# R7FA4L1BD register map
Vendor: Renesas Electronics Corporation; Series: RA4; File version: 1.20.03
CPU: CM33 r0p4, little endian, MPU, FPU, VTOR, 4 interrupt priority bits, 96 interrupts
Registers are 32-bit, read-write, reset 0x0 unless marked. A register's access mark holds for its fields unless they carry their own. Offsets are from the block's base; [hi:lo] are bit positions; 'fields as' and 'values as' point back to an identical list.

## MSTP — Module Stop Control
Base 0x40084000
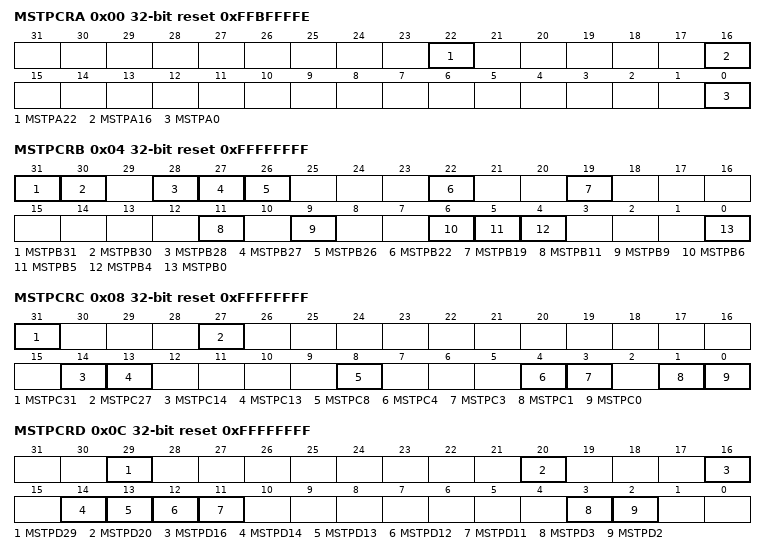
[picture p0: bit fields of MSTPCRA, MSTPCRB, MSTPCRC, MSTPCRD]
0x00 MSTPCRA reset 0xFFBFFFFE — Module Stop Control Register A
  [all] fields
    0=Cancel the module-stop state; 1=Enter the module-stop state
  [22] MSTPA22 — DMA Controller/Data Transfer Controller Module Stop
  [16] MSTPA16 — Sub Oscillation Stop Detection Module Stop
  [0] MSTPA0 — SRAM0 Module Stop
0x04 MSTPCRB reset 0xFFFFFFFF — Module Stop Control Register B
  [all] fields
    values as the fields of MSTPCRA
  [31] MSTPB31 — Serial Communication Interface 0 Module Stop
  [30] MSTPB30 — Serial Communication Interface 1 Module Stop
  [28] MSTPB28 — Serial Communication Interface 3 Module Stop
  [27] MSTPB27 — Serial Communication Interface 4 Module Stop
  [26] MSTPB26 — Serial Communication Interface 5 Module Stop
  [22] MSTPB22 — Serial Communication Interface 9 Module Stop
  [19] MSTPB19 — Serial Peripheral Interface 0 Module Stop
  [11] MSTPB11 — Universal Serial Bus 2.0 FS Interface Module Stop
  [9] MSTPB9 — I2C Bus Interface 0 Module Stop
  [6] MSTPB6 — Quad Serial Peripheral Interface Module Stop
  [5] MSTPB5 — IrDA Interface Module Stop
  [4] MSTPB4 — I3C Bus Interface Module Stop
  [0] MSTPB0 — Serial Interface UARTA Module Stop
0x08 MSTPCRC reset 0xFFFFFFFF — Module Stop Control Register C
  [all] fields
    values as the fields of MSTPCRA
  [31] MSTPC31 — RSIP-E11A Module Stop
  [27] MSTPC27 — Controller Area Network with Flexible Data-Rate Module Stop
  [14] MSTPC14 — Event Link Controller Module Stop
  [13] MSTPC13 — Data Operation Circuit Module Stop
  [8] MSTPC8 — Serial Sound Interface Enhanced Module Stop
  [4] MSTPC4 — Segment LCD Controller Module Stop
  [3] MSTPC3 — Capacitive Touch Sensing Unit Module Stop
  [1] MSTPC1 — Cyclic Redundancy Check Calculator Module Stop
  [0] MSTPC0 — Clock Frequency Accuracy Measurement Circuit Module Stop
0x0C MSTPCRD reset 0xFFFFFFFF — Module Stop Control Register D
  [all] fields
    values as the fields of MSTPCRA
  [29] MSTPD29 — Low-Power Analog Comparator Module Stop
  [20] MSTPD20 — 12-bit D/A Converter Module Stop
  [16] MSTPD16 — 12-bit A/D Converter 0 Module Stop
  [14] MSTPD14 — Port Output Enable for GPT Group A Module Stop
  [13] MSTPD13 — Port Output Enable for GPT Group B Module Stop
  [12] MSTPD12 — Port Output Enable for GPT Group C Module Stop
  [11] MSTPD11 — Port Output Enable for GPT Group D Module Stop
  [3] MSTPD3 — Low Power Asynchronous General Purpose Timer 0 Module Stop
  [2] MSTPD2 — Low Power Asynchronous General Purpose Timer 1 Module Stop
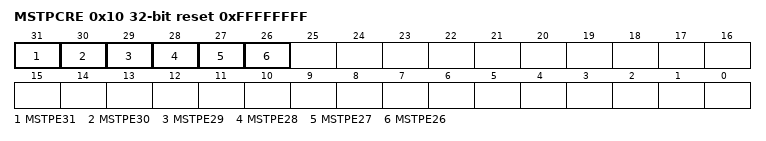
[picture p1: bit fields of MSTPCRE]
0x10 MSTPCRE reset 0xFFFFFFFF — Module Stop Control Register E
  [all] fields
    values as the fields of MSTPCRA
  [31] MSTPE31 — GPT0 Module Stop
  [30] MSTPE30 — GPT1 Module Stop
  [29] MSTPE29 — GPT2 Module Stop
  [28] MSTPE28 — GPT3 Module Stop
  [27] MSTPE27 — GPT4 Module Stop
  [26] MSTPE26 — GPT5 Module Stop

## IIC0WU — IIC0 Wake-up Unit
Base 0x4009F014
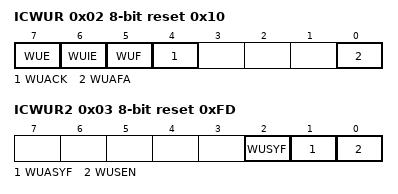
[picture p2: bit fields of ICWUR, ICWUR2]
0x02 ICWUR 8-bit reset 0x10 — I2C Bus Wakeup Unit Register
  [7] WUE — Wakeup Function Enable
    0=Disable wakeup function; 1=Enable wakeup function
  [6] WUIE — Wakeup Interrupt Request Enable
    0=Disable wakeup interrupt request (IIC0_WUI); 1=Enable wakeup interrupt request (IIC0_WUI)
  [5] WUF — Wakeup Event Occurrence Flag
    0=Slave address not matching during wakeup; 1=Slave address matching during wakeup
  [4] WUACK — ACK Bit for Wakeup Mode
  [0] WUAFA — Wakeup Analog Filter Additional Selection
    0=Do not add the wakeup analog filter; 1=Add the wakeup analog filter
0x03 ICWUR2 8-bit reset 0xFD — I2C Bus Wakeup Unit Register 2
  [2] WUSYF ro — Wakeup Function Synchronous Operation Status Flag
    0=IIC asynchronous circuit enable condition; 1=IIC synchronous circuit enable condition
  [1] WUASYF ro — Wakeup Function Asynchronous Operation Status Flag
    0=IIC synchronous circuit enable condition; 1=IIC asynchronous circuit enable condition
  [0] WUSEN — Wakeup Function Synchronous Enable
    0=IIC asynchronous circuit enable; 1=IIC synchronous circuit enable
